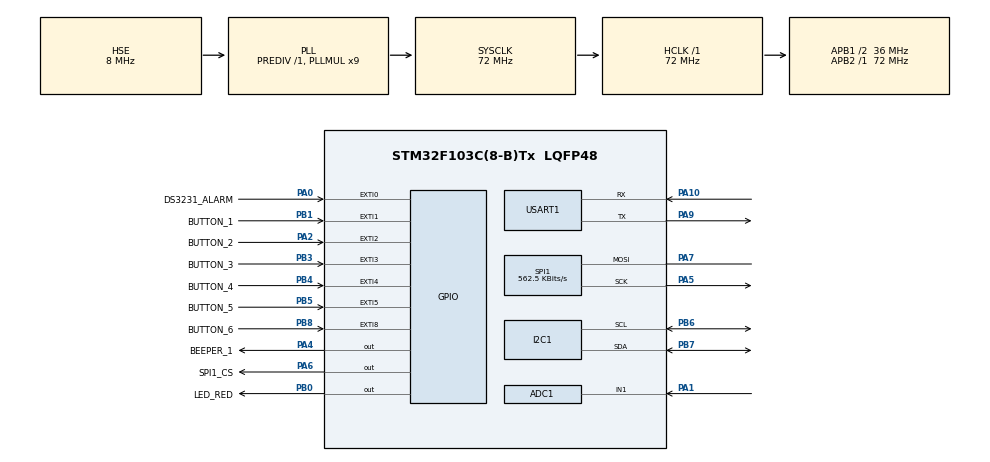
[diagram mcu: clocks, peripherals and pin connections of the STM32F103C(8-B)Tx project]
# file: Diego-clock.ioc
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ADC1.Channel-0\#ChannelRegularConversion=ADC_CHANNEL_1
ADC1.NbrOfConversionFlag=1
ADC1.Rank-0\#ChannelRegularConversion=1
ADC1.SamplingTime-0\#ChannelRegularConversion=ADC_SAMPLETIME_1CYCLE_5
ADC1.master=1
IWDG.Prescaler=IWDG_PRESCALER_16
IWDG.Reload=4000
Mcu.Family=STM32F1
Mcu.Name=STM32F103C(8-B)Tx
Mcu.Package=LQFP48
NVIC.EXTI0_IRQn=true\:0\:0\:false\:false\:true\:true\:true\:true
NVIC.EXTI1_IRQn=true\:0\:0\:false\:false\:true\:true\:true\:true
NVIC.EXTI2_IRQn=true\:0\:0\:false\:false\:true\:true\:true\:true
NVIC.EXTI3_IRQn=true\:0\:0\:false\:false\:true\:true\:true\:true
NVIC.EXTI4_IRQn=true\:0\:0\:false\:false\:true\:true\:true\:true
NVIC.EXTI9_5_IRQn=true\:0\:0\:false\:false\:true\:true\:true\:true
NVIC.PriorityGroup=NVIC_PRIORITYGROUP_4
PA0-WKUP.GPIO_Label=DS3231_ALARM
PA0-WKUP.GPIO_ModeDefaultEXTI=GPIO_MODE_IT_FALLING
PA0-WKUP.GPIO_PuPd=GPIO_PULLUP
PA0-WKUP.Signal=GPXTI0
PA1.Signal=ADCx_IN1
PA10.Mode=Asynchronous
PA10.Signal=USART1_RX
PA13.Mode=Serial_Wire
PA13.Signal=SYS_JTMS-SWDIO
PA14.Mode=Serial_Wire
PA14.Signal=SYS_JTCK-SWCLK
PA2.GPIO_Label=BUTTON_2
PA2.GPIO_ModeDefaultEXTI=GPIO_MODE_IT_FALLING
PA2.GPIO_PuPd=GPIO_PULLUP
PA2.Signal=GPXTI2
PA4.GPIO_Label=BEEPER_1
PA4.GPIO_ModeDefaultOutputPP=GPIO_MODE_OUTPUT_OD
PA4.Signal=GPIO_Output
PA5.Mode=Simplex_Bidirectional_Master
PA5.Signal=SPI1_SCK
PA6.GPIO_Label=SPI1_CS
PA6.GPIO_PuPd=GPIO_PULLUP
PA6.Signal=GPIO_Output
PA7.Mode=Simplex_Bidirectional_Master
PA7.Signal=SPI1_MOSI
PA9.Mode=Asynchronous
PA9.Signal=USART1_TX
PB0.GPIO_Label=LED_RED
PB0.GPIO_ModeDefaultOutputPP=GPIO_MODE_OUTPUT_OD
PB0.Signal=GPIO_Output
PB1.GPIO_Label=BUTTON_1
PB1.GPIO_ModeDefaultEXTI=GPIO_MODE_IT_FALLING
PB1.GPIO_PuPd=GPIO_PULLUP
PB1.Signal=GPXTI1
PB3.GPIO_Label=BUTTON_3
PB3.GPIO_ModeDefaultEXTI=GPIO_MODE_IT_FALLING
PB3.GPIO_PuPd=GPIO_PULLUP
PB3.Signal=GPXTI3
PB4.GPIO_Label=BUTTON_4
PB4.GPIO_ModeDefaultEXTI=GPIO_MODE_IT_FALLING
PB4.GPIO_PuPd=GPIO_PULLUP
PB4.Signal=GPXTI4
PB5.GPIO_Label=BUTTON_5
PB5.GPIO_ModeDefaultEXTI=GPIO_MODE_IT_FALLING
PB5.GPIO_PuPd=GPIO_PULLUP
PB5.Signal=GPXTI5
PB6.GPIO_Pu=GPIO_PULLUP
PB6.Mode=I2C
PB6.Signal=I2C1_SCL
PB7.GPIO_Pu=GPIO_PULLUP
PB7.Mode=I2C
PB7.Signal=I2C1_SDA
PB8.GPIO_Label=BUTTON_6
PB8.GPIO_ModeDefaultEXTI=GPIO_MODE_IT_FALLING
PB8.GPIO_PuPd=GPIO_PULLUP
PB8.Signal=GPXTI8
PC14-OSC32_IN.Mode=LSE-External-Oscillator
PC14-OSC32_IN.Signal=RCC_OSC32_IN
PC15-OSC32_OUT.Mode=LSE-External-Oscillator
PC15-OSC32_OUT.Signal=RCC_OSC32_OUT
PD0-OSC_IN.Mode=HSE-External-Oscillator
PD0-OSC_IN.Signal=RCC_OSC_IN
PD1-OSC_OUT.Mode=HSE-External-Oscillator
PD1-OSC_OUT.Signal=RCC_OSC_OUT
ProjectManager.HeapSize=0x200
ProjectManager.StackSize=0x400
ProjectManager.TargetToolchain=STM32CubeIDE
RCC.ADCPresc=RCC_ADCPCLK2_DIV8
RCC.AHBFreq_Value=72000000
RCC.APB1CLKDivider=RCC_HCLK_DIV2
RCC.APB1Freq_Value=36000000
RCC.APB1TimFreq_Value=72000000
RCC.APB2Freq_Value=72000000
RCC.APB2TimFreq_Value=72000000
RCC.HCLKFreq_Value=72000000
RCC.PLLMUL=RCC_PLL_MUL9
RCC.PLLSourceVirtual=RCC_PLLSOURCE_HSE
RCC.SYSCLKFreq_VALUE=72000000
RCC.SYSCLKSource=RCC_SYSCLKSOURCE_PLLCLK
RCC.USBFreq_Value=72000000
SH.ADCx_IN1.0=ADC1_IN1,IN1
SPI1.BaudRatePrescaler=SPI_BAUDRATEPRESCALER_128
SPI1.CalculateBaudRate=562.5 KBits/s
SPI1.Direction=SPI_DIRECTION_1LINE
SPI1.Mode=SPI_MODE_MASTER
SPI1.VirtualType=VM_MASTER
USART1.VirtualMode=VM_ASYNC
VP_IWDG_VS_IWDG.Mode=IWDG_Activate
board=custom

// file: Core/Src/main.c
/* USER CODE BEGIN Header */
/**
  ******************************************************************************
  * @file           : main.c
  * @brief          : Main program body
  ******************************************************************************
  * @attention
  *
  * Copyright (c) 2022 STMicroelectronics.
  * All rights reserved.
  *
  * This software is licensed under terms that can be found in the LICENSE file
  * in the root directory of this software component.
  * If no LICENSE file comes with this software, it is provided AS-IS.
  *
  ******************************************************************************
  */
/* USER CODE END Header */
#include "main.h"
#include "adc.h"
#include "i2c.h"
#include "iwdg.h"
#include "spi.h"
#include "usart.h"
#include "gpio.h"

/* USER CODE BEGIN Includes */

	#include "digital_clock_for_bedroom_sm.h"

/* USER CODE END Includes */

void SystemClock_Config(void);

int main(void)
{

  /* MCU Configuration--------------------------------------------------------*/

  /* Reset of all peripherals, Initializes the Flash interface and the Systick. */
  HAL_Init();

  /* Configure the system clock */
  SystemClock_Config();

  /* Initialize all configured peripherals */
  MX_GPIO_Init();
  MX_I2C1_Init();
  MX_SPI1_Init();
  MX_USART1_UART_Init();
  MX_IWDG_Init();
  MX_ADC1_Init();
  /* USER CODE BEGIN 2 */

	  Diego_Init();

  /* USER CODE END 2 */

  /* Infinite loop */
  /* USER CODE BEGIN WHILE */
  while (1)
  {
	  Diego_Main();

    /* USER CODE END WHILE */

  }
}

void SystemClock_Config(void)
{
  RCC_OscInitTypeDef RCC_OscInitStruct = {0};
  RCC_ClkInitTypeDef RCC_ClkInitStruct = {0};
  RCC_PeriphCLKInitTypeDef PeriphClkInit = {0};

  /** Initializes the RCC Oscillators according to the specified parameters
  * in the RCC_OscInitTypeDef structure.
  */
  RCC_OscInitStruct.OscillatorType = RCC_OSCILLATORTYPE_LSI|RCC_OSCILLATORTYPE_HSE;
  RCC_OscInitStruct.HSEState = RCC_HSE_ON;
  RCC_OscInitStruct.HSEPredivValue = RCC_HSE_PREDIV_DIV1;
  RCC_OscInitStruct.HSIState = RCC_HSI_ON;
  RCC_OscInitStruct.LSIState = RCC_LSI_ON;
  RCC_OscInitStruct.PLL.PLLState = RCC_PLL_ON;
  RCC_OscInitStruct.PLL.PLLSource = RCC_PLLSOURCE_HSE;
  RCC_OscInitStruct.PLL.PLLMUL = RCC_PLL_MUL9;
  if (HAL_RCC_OscConfig(&RCC_OscInitStruct) != HAL_OK)
  {
    Error_Handler();
  }

  /** Initializes the CPU, AHB and APB buses clocks
  */
  RCC_ClkInitStruct.ClockType = RCC_CLOCKTYPE_HCLK|RCC_CLOCKTYPE_SYSCLK
                              |RCC_CLOCKTYPE_PCLK1|RCC_CLOCKTYPE_PCLK2;
  RCC_ClkInitStruct.SYSCLKSource = RCC_SYSCLKSOURCE_PLLCLK;
  RCC_ClkInitStruct.AHBCLKDivider = RCC_SYSCLK_DIV1;
  RCC_ClkInitStruct.APB1CLKDivider = RCC_HCLK_DIV2;
  RCC_ClkInitStruct.APB2CLKDivider = RCC_HCLK_DIV1;

  if (HAL_RCC_ClockConfig(&RCC_ClkInitStruct, FLASH_LATENCY_2) != HAL_OK)
  {
    Error_Handler();
  }
  PeriphClkInit.PeriphClockSelection = RCC_PERIPHCLK_ADC;
  PeriphClkInit.AdcClockSelection = RCC_ADCPCLK2_DIV8;
  if (HAL_RCCEx_PeriphCLKConfig(&PeriphClkInit) != HAL_OK)
  {
    Error_Handler();
  }
}

void Error_Handler(void)
{
  __disable_irq();
  while (1)
  {
  }
}
